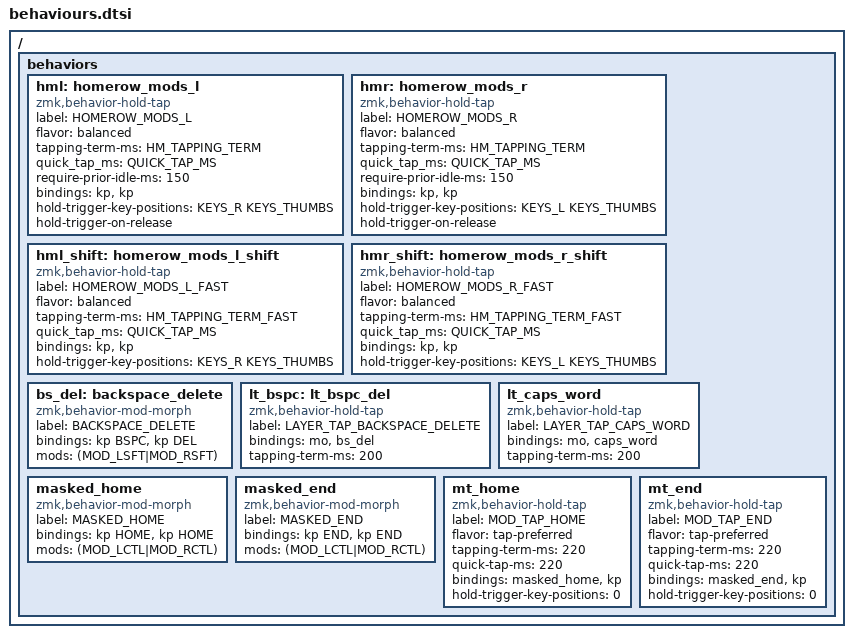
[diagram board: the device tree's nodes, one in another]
// Behaviour Settings variables

#define KEYS_L 0 1 2 3 4 5 12 13 14 15 16 17 24 25 26 27 28 29
#define KEYS_R 6 7 8 9 10 11 18 19 20 21 22 23 30 31 32 33 34 35
#define KEYS_THUMBS 36 37 38 39 40 41 42

#define HM_TAPPING_TERM 300
#define HM_TAPPING_TERM_FAST 200

/ {
    behaviors {
        hml: homerow_mods_l {
            compatible = "zmk,behavior-hold-tap";
            label = "HOMEROW_MODS_L";
            flavor = "balanced";
            #binding-cells = <2>;
            tapping-term-ms = <HM_TAPPING_TERM>;
            quick_tap_ms = <QUICK_TAP_MS>;
            require-prior-idle-ms = <150>;
            bindings = <&kp>, <&kp>;
            hold-trigger-key-positions = <KEYS_R KEYS_THUMBS>;
            hold-trigger-on-release;             // delay positional check until key-release
        };

        hmr: homerow_mods_r {
            compatible = "zmk,behavior-hold-tap";
            label = "HOMEROW_MODS_R";
            flavor = "balanced";
            #binding-cells = <2>;
            tapping-term-ms = <HM_TAPPING_TERM>;
            quick_tap_ms = <QUICK_TAP_MS>;
            require-prior-idle-ms = <150>;
            bindings = <&kp>, <&kp>;
            hold-trigger-key-positions = <KEYS_L KEYS_THUMBS>;
            hold-trigger-on-release;             // delay positional check until key-release
        };

        hml_shift: homerow_mods_l_shift {
            compatible = "zmk,behavior-hold-tap";
            label = "HOMEROW_MODS_L_FAST";
            flavor = "balanced";
            #binding-cells = <2>;
            tapping-term-ms = <HM_TAPPING_TERM_FAST>;
            quick_tap_ms = <QUICK_TAP_MS>;
            // require-prior-idle-ms = <150>;
            bindings = <&kp>, <&kp>;
            hold-trigger-key-positions = <KEYS_R KEYS_THUMBS>;
            // hold-trigger-on-release;             // delay positional check until key-release
        };

        hmr_shift: homerow_mods_r_shift {
            compatible = "zmk,behavior-hold-tap";
            label = "HOMEROW_MODS_R_FAST";
            flavor = "balanced";
            #binding-cells = <2>;
            tapping-term-ms = <HM_TAPPING_TERM_FAST>;
            quick_tap_ms = <QUICK_TAP_MS>;
            // require-prior-idle-ms = <150>;
            bindings = <&kp>, <&kp>;
            hold-trigger-key-positions = <KEYS_L KEYS_THUMBS>;
            // hold-trigger-on-release;             // delay positional check until key-release
        };

        bs_del: backspace_delete {
            compatible = "zmk,behavior-mod-morph";
            label = "BACKSPACE_DELETE";
            #binding-cells = <0>;
            bindings = <&kp BSPC>, <&kp DEL>;
            mods = <(MOD_LSFT|MOD_RSFT)>;
        };

        lt_bspc: lt_bspc_del {
            compatible = "zmk,behavior-hold-tap";
            label = "LAYER_TAP_BACKSPACE_DELETE";
            #binding-cells = <2>;
            bindings = <&mo>, <&bs_del>;
            tapping-term-ms = <200>;
        };

        lt_caps_word: lt_caps_word {
            compatible = "zmk,behavior-hold-tap";
            label = "LAYER_TAP_CAPS_WORD";
            #binding-cells = <2>;
            bindings = <&mo>, <&caps_word>;
            tapping-term-ms = <200>;
        };

        masked_home: masked_home {
            compatible = "zmk,behavior-mod-morph";
            label = "MASKED_HOME";
            #binding-cells = <0>;
            bindings = <&kp HOME>, <&kp HOME>;
            mods = <(MOD_LCTL|MOD_RCTL)>;
        };

        masked_end: masked_end {
            compatible = "zmk,behavior-mod-morph";
            label = "MASKED_END";
            #binding-cells = <0>;
            bindings = <&kp END>, <&kp END>;
            mods = <(MOD_LCTL|MOD_RCTL)>;
        };

        mt_home: mt_home {
            compatible = "zmk,behavior-hold-tap";
            label = "MOD_TAP_HOME";
            flavor = "tap-preferred";
            #binding-cells = <2>;
            tapping-term-ms = <220>;
            quick-tap-ms = <220>;
            bindings = <&masked_home>, <&kp>;
            hold-trigger-key-positions = <0>;
        };

        mt_end: mt_end {
            compatible = "zmk,behavior-hold-tap";
            label = "MOD_TAP_END";
            flavor = "tap-preferred";
            #binding-cells = <2>;
            tapping-term-ms = <220>;
            quick-tap-ms = <220>;
            bindings = <&masked_end>, <&kp>;
            hold-trigger-key-positions = <0>;
        }
    };
};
